# ISD91200B_v1 register map
File version: 1.0
Registers are 32-bit, read-write, reset 0x0 unless marked. A register's access mark holds for its fields unless they carry their own. Offsets are from the block's base; [hi:lo] are bit positions; {n}, {i} and the like mark numbered series; 'fields as' and 'values as' point back to an identical list.

## SPI1 — SPI1 Register Map
Base 0x40038000
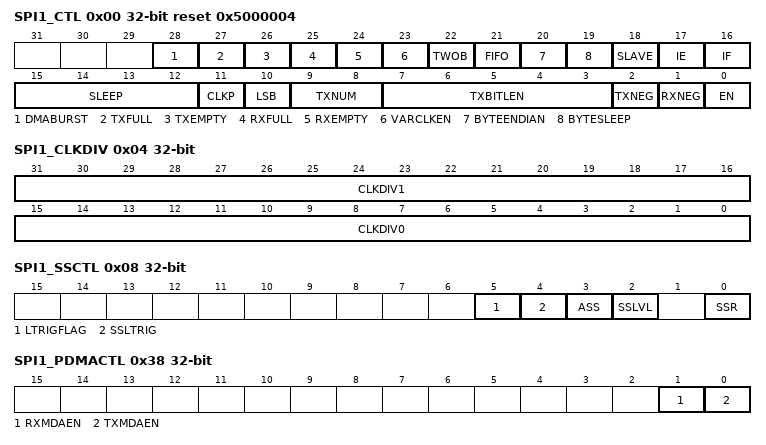
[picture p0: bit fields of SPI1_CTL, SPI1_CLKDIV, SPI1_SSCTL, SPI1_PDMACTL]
0x00 SPI1_CTL reset 0x5000004 — Control and Status Register
  [28] DMABURST — Enable DMA Automatic SS function. When enabled, interface will automatically generate a SS signal for an entire PDMA access transaction.
  [27] TXFULL — Transmit FIFO FULL STATUS
    0=The transmit data FIFO is not full; 1=The transmit data FIFO is full
  [26] TXEMPTY — Transmit FIFO EMPTY STATUS
    0=The transmit data FIFO is not empty; 1=The transmit data FIFO is empty
  [25] RXFULL — Receive FIFO FULL STATUS
    0=The receive data FIFO is not full; 1=The receive data FIFO is full
  [24] RXEMPTY — Receive FIFO EMPTY STATUS
    0=The receive data FIFO is not empty; 1=The receive data FIFO is empty
  [23] VARCLKEN — Variable Clock Enable (Master Only). Note that when enabled, the setting of TXBITLEN must be programmed as 0x10 (16 bits mode)
    0=The serial clock output frequency is fixed and determined only by the value of DIVIDER; 1=SCLK output frequency is variable. The output frequency is determined by the value of VARCLK, DIVIDER, and DIVIDER2
  [22] TWOB — Two Bits Transfer Mode. Note that when enabled in master mode, MOSI data comes from SPI1_TX0 and MOSI data from SPI1_TX1. Likewise SPI1_RX0 receives bit stream from MISO0 and SPI1_RX1 from MISO1. Note that when enabled, the setting of TXNUM must be programmed as 0x00
    0=Disable two-bit transfer mode; 1=Enable two-bit transfer mode
  [21] FIFO — FIFO Mode
    0=No FIFO present on transmit and receive buffer; 1=Enable FIFO on transmit and receive buffer
  [20] BYTEENDIAN — Byte Endian Reorder Function. This function changes the order of bytes sent/received to be least significant physical byte first.
  [19] BYTESLEEP — Insert Sleep interval between Bytes
  [18] SLAVE — Master Slave Mode Control
    0=Master mode; 1=Slave mode
  [17] IE — Interrupt Enable
    0=Disable SPI Interrupt; 1=Enable SPI Interrupt to CPU
  [16] IF — Interrupt Flag. NOTE: This bit is cleared by writing 1 to itself.
    0=Indicates the transfer is not finished yet; 1=Indicates that the transfer is complete. Interrupt is generated to CPU if enabled
  [15:12] SLEEP — Suspend Interval (Master Only) (SLEEP[3:0] + 2) * period of SCLK
  [11] CLKP — Clock Polarity
    0=SCLK idle low; 1=SCLK idle high
  [10] LSB — LSB First
    0=The MSB is transmitted/received first (which bit in SPI1_TX0/1 and SPI1_RX0/1 register that is depends on the TXBITLEN field); 1=The LSB is sent first on the line (bit 0 of SPI1_TX0/1), and the first bit received from the line will be put in the LSB position in the Rx register (bit 0 of SPI1_RX0/1)
  [9:8] TXNUM — Transmit/Receive Word Numbers. This field specifies how many transmit/receive word numbers should be executed in one transfer.
    0=Only one transmit/receive word will be executed in one transfer; 1=Two successive transmit/receive word will be executed in one transfer
  [7:3] TXBITLEN — Transmit Bit Length. This field specifies how many bits are transmitted in one transmit/receive. Up to 32 bits can be transmitted.
    0=32 bit; {v}={v} bit (v=1..31)
  [2] TXNEG — Transmit At Negative Edge
    0=The transmitted data output signal is changed at the rising edge of SCLK; 1=The transmitted data output signal is changed at the falling edge of SCLK
  [1] RXNEG — Receive At Negative Edge
    0=The received data input signal is latched at the rising edge of SCLK; 1=The received data input signal is latched at the falling edge of SCLK
  [0] EN — Go and Busy Status. NOTE: All registers should be set before writing 1 to this EN bit. When a transfer is in progress, writing to any register of the SPI master/slave core has no effect.
    0=Writing 0 to this bit has no effect; 1=Writing 1 to this bit starts the transfer. This bit remains set during the transfer and is automatically cleared after transfer finished
0x04 SPI1_CLKDIV — Clock Divider Register (Master Only)
  [31:16] CLKDIV1 — Clock Divider 2 Register (master only). The value in this field is the 2nd frequency divider of the system clock, PCLK, to generate the serial clock on the output SCLK. The desired frequency is obtained according to the following equation:
  [15:0] CLKDIV0 — Clock Divider Register (master only). The value in this field is the frequency division of the system clock, PCLK, to generate the serial clock on the output SCLK. The desired frequency is obtained according to the following equation: . In slave mode, the period of SPI clock driven by a master shall satisfy . In other words, the maximum frequency of SCLK clock is one fifth of the SPI peripheral clock.
0x08 SPI1_SSCTL — Slave Select Register
  [5] LTRIGFLAG — Level Trigger Flag. When the SSLTRIG bit is set in slave mode, this bit can be read to indicate the received bit number is met the requirement or not. Note: This bit is READ only
    0=One of the received number and the received bit length doesn't meet the requirement in one transfer; 1=The received number and received bits met the requirement which defines in TXNUM and TXBITLEN among one transfer
  [4] SSLTRIG — Slave Select Level Trigger (Slave only)
    0=The input slave select signal is edge-trigger. This is the default value; 1=The slave select signal will be level-trigger. It depends on SSLVL to decide the signal is active low or active high
  [3] ASS — Automatic Slave Select (Master only)
    0=If this bit is cleared, slave select signals are asserted and de-asserted by setting and clearing related bits in SSCTL register; 1=If this bit is set, SPISS signals are generated automatically. It means that device/slave select signal, which is set in SSCTL register is asserted by the SPI controller when transmit/receive is started by setting EN, and is de-asserted after each transmit/receive is finished
  [2] SSLVL — Slave Select Active Level. It defines the active level of device/slave select signal (SPISSx0/1).
    0=The slave select signal SPISSx0/1 is active at low-level/falling-edge; 1=The slave select signal SPISSx0/1 is active at high-level/rising-edge
  [0] SSR — Slave Select Register (Master only). If ASS bit is cleared, writing 1 to any bit location of this field sets the proper SPISSx0/1 line to an active state and writing 0 sets the line back to inactive state. If ASS bit is set, writing 1 to any bit location of this field will select appropriate SPISS line to be automatically driven to active state for the duration of the transmit/receive, and will be driven to inactive state for the rest of the time. (The active level of SPISSx0/1 is specified in SSLVL). Note: SPISS is always defined as device/slave select input signal in slave mode.
0x10 SPI1_RX0 ro — Data Receive Register 0
  [31:0] RX — Data Receive Register. The Data Receive Registers hold the value of received data of the last executed transfer. Valid bits depend on the transmit bit length field in the SPI1_CTL register. For example, if TXBITLEN is set to 0x08 and TXNUM is set to 0x0, bit SPI1_RX0[7:0] holds the received data. NOTE: The Data Receive Registers are read only registers.
0x14 SPI1_RX1 ro — Data Receive Register 1
  fields as SPI1_RX0
0x20 SPI1_TX0 wo — Data Transmit Register 0
  [31:0] TX — Data Transmit Register. The Data Transmit Registers hold the data to be transmitted in the next transfer. Valid bits depend on the transmit bit length field in the SPI1_CTL register. For example, if TXBITLEN is set to 0x08 and the TXNUM is set to 0x0, the bit SPI1_TX0[7:0] will be transmitted in next transfer. If TXBITLEN is set to 0x00 and TXNUM is set to 0x1, the core will perform two 32-bit transmit/receive successive using the same setting (the order is SPI1_TX0[31:0], SPI1_TX1[31:0]).
0x24 SPI1_TX1 wo — Data Transmit Register 1
  fields as SPI1_TX0
0x34 SPI1_VARCLK reset 0x7FFF87 — Variable Clock Pattern Register
  [31:0] VARCLK — Variable Clock Pattern. The value in this field is the frequency pattern of the SPI clock. If the bit field of VARCLK is '0', the output frequency of SCLK is given by the value of DIVIDER. If the bit field of VARCLK is '1', the output frequency of SCLK is given by the value of CLKDIV1. Refer to register CLKDIV0. Refer to Figure 562 Variable Serial Clock Frequency paragraph for detailed description.
0x38 SPI1_PDMACTL — SPI PDMA Control Register
  [1] RXMDAEN — Receive DMA Start. Set this bit to 1 will start the receive DMA process. SPI module will issue request to DMA module automatically.
    0=Disable; 1=Enable
  [0] TXMDAEN — Transmit DMA Start. Set this bit to 1 will start the transmit DMA process. SPI module will issue request to DMA module automatically. If using DMA mode to transfer data, remember not to set EN bit of SPI_CTL register. The DMA controller inside SPI module will set it automatically whenever necessary.
    0=Disable; 1=Enable
